# CC2340R5 register map
File version: 1.0
CPU: CM0P 1.0, other endian, MPU, FPU, 3 interrupt priority bits
Registers are 32-bit, read-write, reset 0x0 unless marked. A register's access mark holds for its fields unless they carry their own. Offsets are from the block's base; [hi:lo] are bit positions; 'fields as' and 'values as' point back to an identical list.

## CKMD — Clock Controller
Base 0x40001000
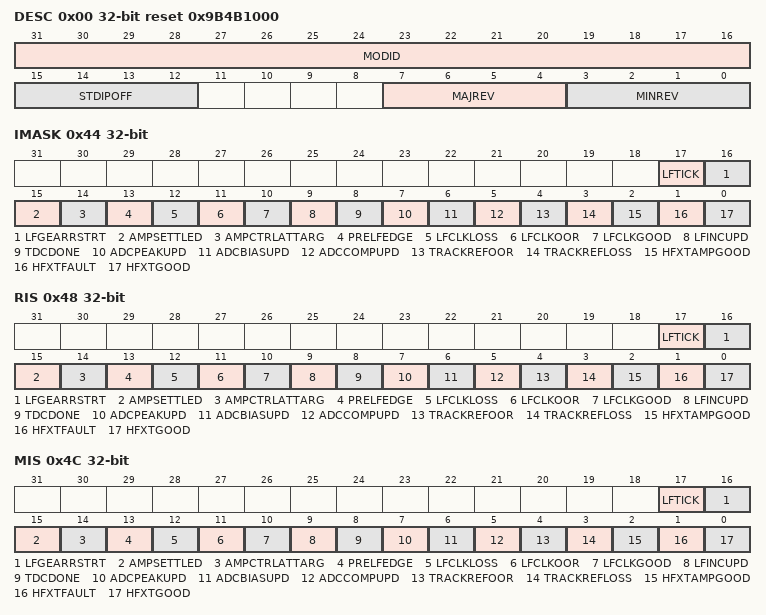
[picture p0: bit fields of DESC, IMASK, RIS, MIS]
0x00 DESC reset 0x9B4B1000 — Description Register. This register provides IP module ID, revision information, instance index and standard MMR registers offset.
  [31:16] MODID ro — [31:16] Module identifier used to uniquely identify this IP.
  [15:12] STDIPOFF ro — [15:12] Standard IP MMR block offset. Standard IP MMRs are the set of from aggregated IRQ registers till DTB. 0: Standard IP MMRs do not exist 0x1-0xF: Standard IP MMRs begin at offset of (64*STDIPOFF from the base IP address) NOTE: This IP does not have DTB as part of the Standard IP MMRs. It uses DTBCTL instead.
  [7:4] MAJREV ro — [7:4] Major revision of IP (0-15).
  [3:0] MINREV ro — [3:0] Minor revision of IP (0-15).
0x44 IMASK — Interrupt mask. This register selects interrupt sources which are allowed to pass from RIS to MIS when the corresponding bit-fields are set to 1.
  [17] LFTICK — [17:17] 32kHz TICK to RTC and WDT. Either derived from selected LFCLK or generated from CLKULL in absence of LFCLK.
  [16] LFGEARRSTRT — [16:16] LFINC filter gearing restart. Indicates that the LFINC filter restarted gearing. Subsequent LFINC estimates may have higher variation.
  [15] AMPSETTLED — [15:15] HFXT Amplitude compensation - settled Indicates that the amplitude compensation FSM has reached the SETTLED or TCXOMODE state, and the controls configured in HFXTTARG or HFXTDYN are reached.
  [14] AMPCTRLATTARG — [14:14] HFXT Amplitude compensation - controls at target Indicates that the control values configured in HFXTTARG or HFXTDYN are reached. Applies to Q1CAP, Q2CAP and IREF.
  [13] PRELFEDGE — [13:13] Pre-LF clock edge detect. Indicates that a positive edge occured on the selected pre-LF clock LFCLKSEL.PRE. Can be used by software to confirm that a LF clock source is running and within the expected frequency, before selecting it as the main LF clock source.
  [12] LFCLKLOSS — [12:12] LF clock is lost. Indicates that no LF clock edge occured for ~49us (~1.6 times nominal period). The system will automatically fall-back to generating LFTICK based on CLKULL, to avoid timing corruption. Note that this signal is NOT related to the analog LF clock-loss detector which can reset the device during STANDBY.
  [11] LFCLKOOR — [11:11] LF clock period out-of-range. Indicates that a LF clock period was measured to be out-of-range, according to LFQUALCTL.MAXERR.
  [10] LFCLKGOOD — [10:10] LF clock good. Indicates that the LF clock is good, according to the configuration in LFQUALCTL.
  [9] LFINCUPD — [9:9] LFINC updated. Indicates that a new LFINC measurement value is available in LFCLKSTAT.LFINC.
  [8] TDCDONE — [8:8] TDC done event. Indicates that the TDC measurement is done.
  [7] ADCPEAKUPD — [7:7] HFXT-ADC PEAK measurement update event. Indicates that the HFXT-ADC PEAK measurement is done.
  [6] ADCBIASUPD — [6:6] HFXT-ADC BIAS measurement update event. Indicates that the HFXT-ADC BIAS measurement is done.
  [5] ADCCOMPUPD — [5:5] HFXT-ADC comparison update event. Indicates that the HFXT-ADC comparison is done.
  [4] TRACKREFOOR — [4:4] Out-of-range indication from the tracking loop. Indicates that the selected reference clock frequency of the tracking loop is out-of-range.
  [3] TRACKREFLOSS — [3:3] Clock loss indication from the tracking loop. Indicates that the selected reference clock of the tracking loop is lost.
  [2] HFXTAMPGOOD — [2:2] HFXT amplitude good indication.
  [1] HFXTFAULT — [1:1] HFXT fault indication. Indicates that HFXT did not start correctly, or its frequency is too low. HFXT will not recover from this fault and has to be restarted. This is only a one-time check at HFXT startup.
  [0] HFXTGOOD — [0:0] HFXT good indication. Indicates that HFXT started correctly. The frequency is not necessarily good enough for radio operation. This is only a one-time check at HFXT startup.
0x48 RIS — Raw interrupt status. This register reflects the state of all pending interrupts, regardless of masking. This register allows the user to implement a poll scheme. A flag set in this register can be cleared by writing 1 to the corresponding ICLR register bit.
  [17] LFTICK ro — [17:17] 32kHz TICK to RTC and WDT. Either derived from selected LFCLK or generated from CLKULL in absence of LFCLK.
  [16] LFGEARRSTRT ro — [16:16] LFINC filter gearing restart. Indicates that the LFINC filter restarted gearing. Subsequent LFINC estimates may have higher variation.
  [15] AMPSETTLED ro — [15:15] HFXT Amplitude compensation - settled Indicates that the amplitude compensation FSM has reached the SETTLED or TCXOMODE state, and the controls configured in HFXTTARG or HFXTDYN are reached.
  [14] AMPCTRLATTARG ro — [14:14] HFXT Amplitude compensation - controls at target Indicates that the control values configured in HFXTTARG or HFXTDYN are reached. Applies to Q1CAP, Q2CAP and IREF.
  [13] PRELFEDGE ro — [13:13] Pre-LF clock edge detect. Indicates that a positive edge occured on the selected pre-LF clock LFCLKSEL.PRE. Can be used by software to confirm that a LF clock source is running and within the expected frequency, before selecting it as the main LF clock source.
  [12] LFCLKLOSS ro — [12:12] LF clock is lost. Indicates that no LF clock edge occured for ~49us (~1.6 times nominal period). The system will automatically fall-back to generating LFTICK based on CLKULL, to avoid timing corruption. Note that this signal is NOT related to the analog LF clock-loss detector which can reset the device during STANDBY.
  [11] LFCLKOOR ro — [11:11] LF clock period out-of-range. Indicates that a LF clock period was measured to be out-of-range, according to LFQUALCTL.MAXERR.
  [10] LFCLKGOOD ro — [10:10] LF clock good. Indicates that the LF clock is good, according to the configuration in LFQUALCTL.
  [9] LFINCUPD ro — [9:9] LFINC updated. Indicates that a new LFINC measurement value is available in LFCLKSTAT.LFINC.
  [8] TDCDONE ro — [8:8] TDC done event. Indicates that the TDC measurement is done.
  [7] ADCPEAKUPD ro — [7:7] HFXT-ADC PEAK measurement update event. Indicates that the HFXT-ADC PEAK measurement is done.
  [6] ADCBIASUPD ro — [6:6] HFXT-ADC BIAS measurement update event. Indicates that the HFXT-ADC BIAS measurement is done.
  [5] ADCCOMPUPD ro — [5:5] HFXT-ADC comparison update event. Indicates that the HFXT-ADC comparison is done.
  [4] TRACKREFOOR ro — [4:4] Out-of-range indication from the tracking loop. Indicates that the selected reference clock frequency of the tracking loop is out-of-range.
  [3] TRACKREFLOSS ro — [3:3] Clock loss indication from the tracking loop. Indicates that the selected reference clock of the tracking loop is lost.
  [2] HFXTAMPGOOD ro — [2:2] HFXT amplitude good indication.
  [1] HFXTFAULT ro — [1:1] HFXT fault indication. Indicates that HFXT did not start correctly, or its frequency is too low. HFXT will not recover from this fault and has to be restarted. This is only a one-time check at HFXT startup.
  [0] HFXTGOOD ro — [0:0] HFXT good indication. Indicates that HFXT started correctly. The frequency is not necessarily good enough for radio operation. This is only a one-time check at HFXT startup.
0x4C MIS — Masked interrupt status. This register is simply a bitwise AND of the contents of IMASK and RIS.*] registers. A flag set in this register can be cleared by writing 1 to the corresponding ICLR register bit.
  fields as RIS
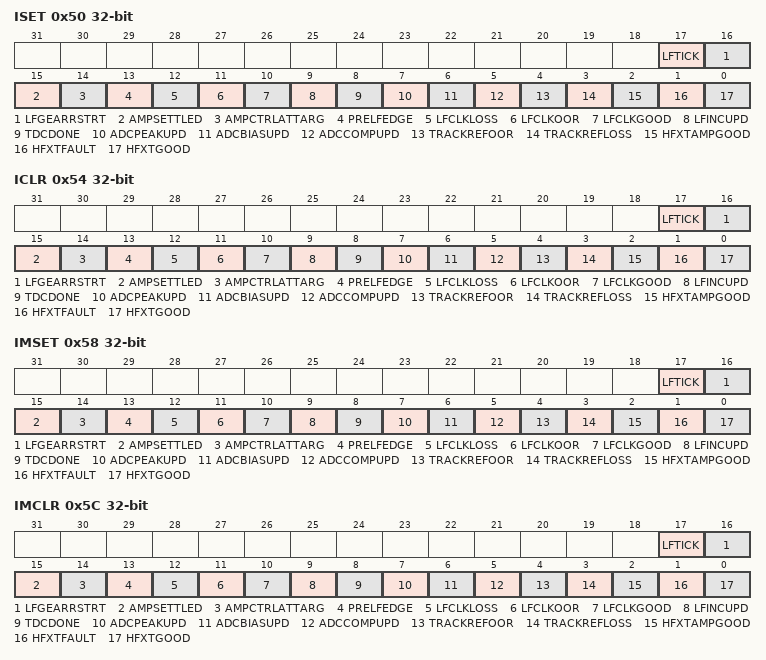
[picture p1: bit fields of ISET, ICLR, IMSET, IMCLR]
0x50 ISET — Interrupt set register. This register can used by software for diagnostics and safety checking purposes. Writing a 1 to a bit in this register will set the event and the corresponding RIS bit also gets set. If the corresponding IMASK bit is set, then the corresponding MIS register bit also gets set.
  [17] LFTICK wo — [17:17] 32kHz TICK to RTC and WDT. Either derived from selected LFCLK or generated from CLKULL in absence of LFCLK.
  [16] LFGEARRSTRT wo — [16:16] LFINC filter gearing restart. Indicates that the LFINC filter restarted gearing. Subsequent LFINC estimates may have higher variation.
  [15] AMPSETTLED wo — [15:15] HFXT Amplitude compensation - settled Indicates that the amplitude compensation FSM has reached the SETTLED or TCXOMODE state, and the controls configured in HFXTTARG or HFXTDYN are reached.
  [14] AMPCTRLATTARG wo — [14:14] HFXT Amplitude compensation - controls at target Indicates that the control values configured in HFXTTARG.Q1CAP, HFXTTARG.Q2CAP and HFXTTARG.IREF or HFXTDYN.Q1CAP, HFXTDYN.Q2CAP and HFXTDYN.IREF are reached.
  [13] PRELFEDGE wo — [13:13] Pre-LF clock edge detect. Indicates that a positive edge occured on the selected pre-LF clock LFCLKSEL.PRE. Can be used by software to confirm that a LF clock source is running and within the expected frequency, before selecting it as the main LF clock source.
  [12] LFCLKLOSS wo — [12:12] LF clock is lost. Indicates that no LF clock edge occured for ~49us (~1.6 times nominal period). The system will automatically fall-back to generating LFTICK based on CLKULL, to avoid timing corruption. Note that this signal is NOT related to the analog LF clock-loss detector which can reset the device during STANDBY.
  [11] LFCLKOOR wo — [11:11] LF clock period out-of-range. Indicates that a LF clock period was measured to be out-of-range, according to LFQUALCTL.MAXERR.
  [10] LFCLKGOOD wo — [10:10] LF clock good. Indicates that the LF clock is good, according to the configuration in LFQUALCTL.
  [9] LFINCUPD wo — [9:9] LFINC updated. Indicates that a new LFINC measurement value is available in LFCLKSTAT.LFINC.
  [8] TDCDONE wo — [8:8] TDC done event. Indicates that the TDC measurement is done.
  [7] ADCPEAKUPD wo — [7:7] HFXT-ADC PEAK measurement update event. Indicates that the HFXT-ADC PEAK measurement is done.
  [6] ADCBIASUPD wo — [6:6] HFXT-ADC BIAS measurement update event. Indicates that the HFXT-ADC BIAS measurement is done.
  [5] ADCCOMPUPD wo — [5:5] HFXT-ADC comparison update event. Indicates that the HFXT-ADC comparison is done.
  [4] TRACKREFOOR wo — [4:4] Out-of-range indication from the tracking loop. Indicates that the selected reference clock frequency of the tracking loop is out-of-range.
  [3] TRACKREFLOSS wo — [3:3] Clock loss indication from the tracking loop. Indicates that the selected reference clock of the tracking loop is lost.
  [2] HFXTAMPGOOD wo — [2:2] HFXT amplitude good indication.
  [1] HFXTFAULT wo — [1:1] HFXT fault indication. Indicates that HFXT did not start correctly, or its frequency is too low. HFXT will not recover from this fault and has to be restarted. This is only a one-time check at HFXT startup.
  [0] HFXTGOOD wo — [0:0] HFXT good indication. Indicates that HFXT started correctly. The frequency is not necessarily good enough for radio operation. This is only a one-time check at HFXT startup.
0x54 ICLR — Interrupt clear register. This register allows software to clear interrupts. Writing a 1 to a bit in this register will clear the event and the corresponding RIS bit also gets cleared. If the corresponding IMASK bit is set, then the corresponding MIS register bit also gets cleared.
  [17] LFTICK wo — [17:17] 32kHz TICK to RTC and WDT. Either derived from selected LFCLK or generated from CLKULL in absence of LFCLK.
  [16] LFGEARRSTRT wo — [16:16] LFINC filter gearing restart. Indicates that the LFINC filter restarted gearing. Subsequent LFINC estimates may have higher variation.
  [15] AMPSETTLED wo — [15:15] HFXT Amplitude compensation - settled Indicates that the amplitude compensation FSM has reached the SETTLED or TCXOMODE state, and the controls configured in HFXTTARG or HFXTDYN are reached.
  [14] AMPCTRLATTARG wo — [14:14] HFXT Amplitude compensation - controls at target Indicates that the control values configured in HFXTTARG or HFXTDYN are reached. Applies to Q1CAP, Q2CAP and IREF.
  [13] PRELFEDGE wo — [13:13] Pre-LF clock edge detect. Indicates that a positive edge occured on the selected pre-LF clock LFCLKSEL.PRE. Can be used by software to confirm that a LF clock source is running and within the expected frequency, before selecting it as the main LF clock source.
  [12] LFCLKLOSS wo — [12:12] LF clock is lost. Indicates that no LF clock edge occured for ~49us (~1.6 times nominal period). The system will automatically fall-back to generating LFTICK based on CLKULL, to avoid timing corruption. Note that this signal is NOT related to the analog LF clock-loss detector which can reset the device during STANDBY.
  [11] LFCLKOOR wo — [11:11] LF clock period out-of-range. Indicates that a LF clock period was measured to be out-of-range, according to LFQUALCTL.MAXERR.
  [10] LFCLKGOOD wo — [10:10] LF clock good. Indicates that the LF clock is good, according to the configuration in LFQUALCTL.
  [9] LFINCUPD wo — [9:9] LFINC updated. Indicates that a new LFINC measurement value is available in LFCLKSTAT.LFINC.
  [8] TDCDONE wo — [8:8] TDC done event. Indicates that the TDC measurement is done.
  [7] ADCPEAKUPD wo — [7:7] HFXT-ADC PEAK measurement update event. Indicates that the HFXT-ADC PEAK measurement is done.
  [6] ADCBIASUPD wo — [6:6] HFXT-ADC BIAS measurement update event. Indicates that the HFXT-ADC BIAS measurement is done.
  [5] ADCCOMPUPD wo — [5:5] HFXT-ADC comparison update event. Indicates that the HFXT-ADC comparison is done.
  [4] TRACKREFOOR wo — [4:4] Out-of-range indication from the tracking loop. Indicates that the selected reference clock frequency of the tracking loop is out-of-range.
  [3] TRACKREFLOSS wo — [3:3] Clock loss indication from the tracking loop. Indicates that the selected reference clock of the tracking loop is lost.
  [2] HFXTAMPGOOD wo — [2:2] HFXT amplitude good indication.
  [1] HFXTFAULT wo — [1:1] HFXT fault indication. Indicates that HFXT did not start correctly, or its frequency is too low. HFXT will not recover from this fault and has to be restarted. This is only a one-time check at HFXT startup.
  [0] HFXTGOOD wo — [0:0] HFXT good indication. Indicates that HFXT started correctly. The frequency is not necessarily good enough for radio operation. This is only a one-time check at HFXT startup.
0x58 IMSET — Interrupt mask set register. Writing a 1 to a bit in this register will set the corresponding IMASK bit.
  fields as ICLR
0x5C IMCLR — Interrupt mask clear register. Writing a 1 to a bit in this register will clear the corresponding IMASK bit.
  fields as ICLR
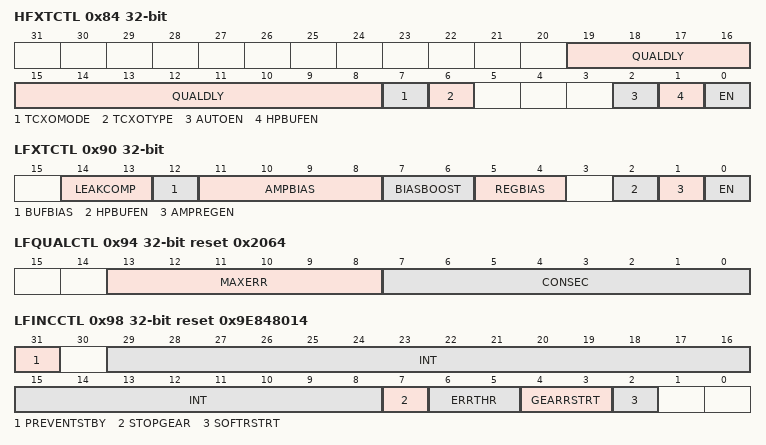
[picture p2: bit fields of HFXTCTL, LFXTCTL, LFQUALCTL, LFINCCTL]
0x84 HFXTCTL — High frequency crystal control
  [19:8] QUALDLY — [19:8] Skip potentially unstable clock cycles after enabling HFXT. Number of cycles skipped is 8*QUALDLY.
  [7] TCXOMODE — [7:7] Temperature compensated crystal oscillator mode. Set this bit if a TXCO is connected.
  [6] TCXOTYPE — [6:6] Type of temperature compensated crystal used. Only has effect if TCXOMODE is set.
    1=CMOS (Use with CMOS TCXO); 0=CLIPPEDSINE (Use with clipped-sine TCXO)
  [2] AUTOEN — [2:2] Automatic HFXT enable. If this bit is set, EN will automatically be set at wakeup or before (using pre-wake mechanism in PMCTL).
  [1] HPBUFEN — [1:1] High performance clock buffer enable. This bit controls the clock output for the RF PLL. It is required for radio operation.
  [0] EN — [0:0] HFXT enable. Setting this bit will enable HFXT. It will automatically be cleared upon STANDBY entry. If AUTOEN is set, this bit will be set automatically on wakeup or before (pre-wake mechanism in PMCTL).
0x8C LFOSCCTL — Low frequency oscillator control
  [0] EN — [0:0] LFOSC enable
0x90 LFXTCTL — Low frequency crystal control
  [14:13] LEAKCOMP — [14:13] Leakage compensation control
    3=OFF (No leakage compensation); 1=HALF (Half leakage compensation); 0=FULL (Full leakage compensation)
  [12] BUFBIAS — [12:12] Control the BIAS current of the input amp in LP buffer
    1=MAX (Maximum bias current: 50nA); 0=MIN (Minimum bias current: 25nA)
  [11:8] AMPBIAS — [11:8] Adjust current mirror ratio into oscillator core. This value is depending on crystal and is set by FW. This field uses a 2's complement encoding.
  [7:6] BIASBOOST — [7:6] Boost oscillator amplitude This value depends on the crystal and needs to be configured by Firmware.
  [5:4] REGBIAS — [5:4] Regulation loop bias resistor value This value depends on the crystal and needs to be configured by Firmware.
  [2] HPBUFEN — [2:2] Control the buffer used. In normal operation, low-power buffer is used in all device modes. The high-performance buffer is only used for test purposes.
  [1] AMPREGEN — [1:1] Amplitude regulation loop enable
  [0] EN — [0:0] LFXT enable
0x94 LFQUALCTL reset 0x2064 — Low frequency clock qualification control
  [13:8] MAXERR — [13:8] Maximum LFCLK period error. Value given in microseconds, 3 integer bits + 3 fractional bits.
  [7:0] CONSEC — [7:0] Number of consecutive times the LFCLK period error has to be smaller than MAXERR to be considered "good". Setting this value to 0 will bypass clock qualification, and the "good" indicator will always be 1.
0x98 LFINCCTL reset 0x9E848014 — Low frequency time increment control
  [31] PREVENTSTBY — [31:31] Controls if the LFINC filter prevents STANBY entry until settled.
    1=ON (Enable. Prevent STANDBY entry.); 0=OFF (Disable. Do not prevent STANDBY entry.)
  [29:8] INT — [29:8] Integral part of the LFINC filter. This value is updated by Hardware to reflect the current state of the filter. It can also be written to change the current state.
  [7] STOPGEAR — [7:7] Controls the final gear of the LFINC filter.
    1=HIGH (Highest final gear. Best dynamic frequency tracking, but higher variation in filter value.); 0=LOW (Lowest final gear. Best settling, but less dynamic frequency tracking.)
  [6:5] ERRTHR — [6:5] Controls the threshold for gearing restart of the LFINC filter. Only effective if GEARRSTRT is not ONETHR or TWOTHR.
    3=SMALL (Restart gearing on small error. Potentially more false restarts, faster response on small frequency shifts.); 2=MIDSMALL (Middle value towards SMALL.); 1=MIDLARGE (Middle value towards LARGE.); 0=LARGE (Restart gearing on large error. Fewer false restarts, slower response on small frequency shifts.)
  [4:3] GEARRSTRT — [4:3] Controls gearing restart of the LFINC filter.
    2=TWOTHR (Restart gearing when the error accumulator crosses the threshold twice in a row.); 1=ONETHR (Restart gearing when the error accumulator crosses the threshold once.); 0=NEVER (Never restart gearing. Very stable filter value, but very slow response on frequency changes.)
  [2] SOFTRSTRT — [2:2] Use a higher gear after re-enabling / wakeup. The filter will require 16-24 LFCLK periods to settle (depending on STOPGEAR), but may respond faster to frequency changes during STANDBY.
    1=ON (Use soft gearing restarts); 0=OFF (Don't use soft gearing restarts)
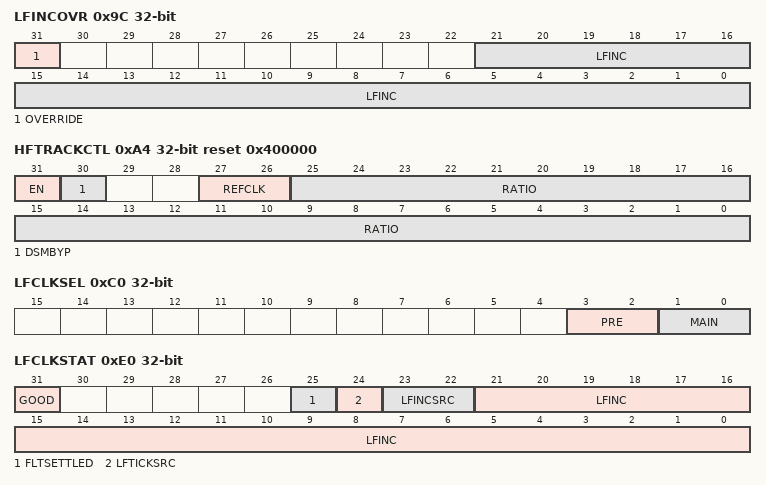
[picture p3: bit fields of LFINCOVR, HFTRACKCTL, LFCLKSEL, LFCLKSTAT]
0x9C LFINCOVR — Low frequency time increment override control
  [31] OVERRIDE — [31:31] Override LF increment Use the value provided in LFINC instead of the value calculated by Hardware.
  [21:0] LFINC — [21:0] LF increment value This value is used when OVERRIDE is set to 1. Otherwise the value is calculated automatically.
0xA4 HFTRACKCTL reset 0x400000 — High frequency tracking loop control
  [31] EN — [31:31] Enable tracking loop.
  [30] DSMBYP — [30:30] Bypass Delta-Sigma-Modulation of fine trim.
  [27:26] REFCLK — [27:26] Select the reference clock for the tracking loop. Change only while the tracking loop is disabled.
    2=GPI (Select GPI as reference clock.); 1=LRF (Select LRF reference clock.); 0=HFXT (Select HFXT as reference clock.)
  [25:0] RATIO — [25:0] Reference clock ratio. RATIO = 24MHz / (2*reference-frequency) * 2^24 Commonly used reference clock frequencies are provided as enumerations.
    0x3000000=REF4M (Use for 4MHz reference clock); 0x1800000=REF8M (Use for 8MHz reference clock); 0x400000=REF48M (Use for 48MHz reference clock)
0xAC NABIASCTL — Nanoamp-bias control
  [0] EN — [0:0] Enable nanoamp-bias
0xB0 LFMONCTL — Low-frequency clock-monitor control
  [0] EN — [0:0] Enable LFMONITOR. Enable only after a LF clock source has been selected, enabled and is stable. If LFMONITOR detects a clock loss, the system will be reset.
0xC0 LFCLKSEL — Low frequency clock selection
  [3:2] PRE — [3:2] Select low frequency clock source for the PRELFCLK interrupt. Can be used by Software to confirm that the clock is running and it's frequency is good, before selecting it in MAIN.
    3=EXTLF (External LF clock through GPI.); 2=LFXT (Low frequency crystal oscillator); 1=LFOSC (Low frequency on-chip oscillator); 0=NONE (No clock. Output will be tied low.)
  [1:0] MAIN — [1:0] Select the main low frequency clock source. If running, this clock will be used to generate LFTICK and as CLKULL during STANDBY. If not running, LFTICK will be generated from HFOSC and STANDBY entry will be prevented.
    3=EXTLF (External LF clock through GPI.); 2=LFXT (Low frequency crystal oscillator); 1=LFOSC (Low frequency on-chip oscillator); 0=FAKE (No LF clock selected. LFTICK will be generated from HFOSC, STANDBY entry will be prevented.)
0xC8 ADCCLKSEL — ADC clock selection
  [1:0] SRC — [1:0] Select ADC clock source Change only while ADC is disabled.
    1=HFXT (48MHz HFXT); 0=CLKSVT (48MHz CLKSVT)
0xE0 LFCLKSTAT — Low-frequency clock status
  [31] GOOD ro — [31:31] Low frequency clock good Note: This is only a coarse frequency check based on LFQUALCTL. The clock may not be accurate enough for timing purposes.
  [25] FLTSETTLED ro — [25:25] LFINC filter is running and settled.
  [24] LFTICKSRC ro — [24:24] Source of LFTICK.
    1=FAKE (LFTICK generated from CLKULL (LFCLK not available)); 0=LFCLK (LFTICK generated from the selected LFCLK)
  [23:22] LFINCSRC ro — [23:22] Source of LFINC used by the RTC. This value depends on LFINCOVR.OVERRIDE, LF clock availability, HF tracking loop status and the device state (ACTIVE/STANDBY).
    3=FAKE (Using FAKE LFTICKs with corresponding LFINC value.); 2=OVERRIDE (Using override value from LFINCOVR.LFINC); 1=AVG (Using filtered / average value. This value is updated by hardware and can be read and updated in LFINCCTL.INT.); 0=MEAS (Using measured value. This value is updated by hardware and can be read from LFINC.)
  [21:0] LFINC ro — [21:0] Measured value of LFINC. Given in microseconds with 16 fractional bits. This value is calculated by Hardware. It is the LFCLK period according to CLKULL cycles.
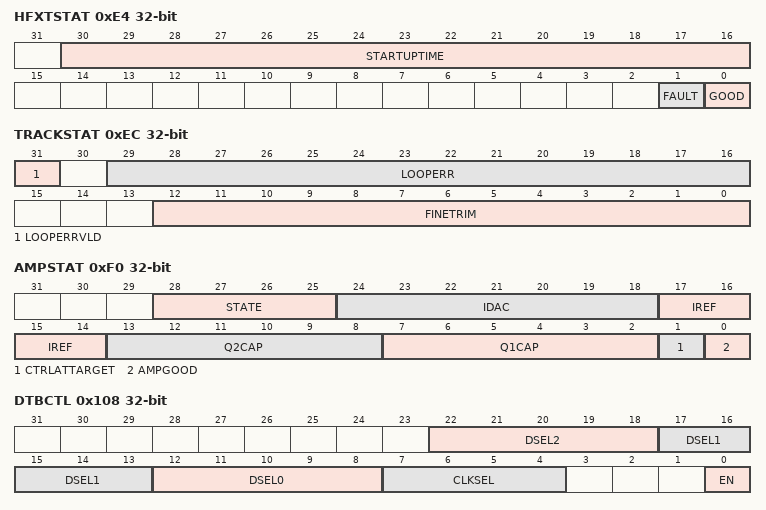
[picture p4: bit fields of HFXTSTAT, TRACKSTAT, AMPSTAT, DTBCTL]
0xE4 HFXTSTAT — HFXT status information
  [30:16] STARTUPTIME ro — [30:16] HFXT startup time Can be used by software to plan starting HFXT ahead in time. Measured whenever HFXT is enabled in CLKULL periods (24MHz), from HFXTCTL.EN until the clock is good for radio operation (amplitude compensation is settled).
  [1] FAULT ro — [1:1] HFXT clock fault Indicates a lower than expected HFXT frequency. HFXT will not recover from this fault, disabling and re-enabling HFXT is required.
  [0] GOOD ro — [0:0] HFXT clock available. The frequency is not necessarily good enough for radio operation.
0xEC TRACKSTAT — HFOSC tracking loop status information
  [31] LOOPERRVLD ro — [31:31] Current HFOSC tracking error valid This bit is one if the tracking loop is running and the error value is valid.
  [29:16] LOOPERR ro — [29:16] Current HFOSC tracking error
  [12:0] FINETRIM ro — [12:0] Current HFOSC Fine-trim value This field uses the internal fractional representation (sign, 4 integer bits, 8 fractional bits). The actual trim value applied to the oscillator is delta-sigma modulated 5 bits non-signed (inverted sign bit + integer bits).
0xF0 AMPSTAT — HFXT Amplitude Compensation Status
  [28:25] STATE ro — [28:25] Current AMPCOMP FSM state.
    15=SETTLED (Settled state); 14=UPDATEUP (Amplitude up correction); 12=TXCOMODE (TCXO settled state); 10=SHUTDN0 (First shutdown state); 7=INJWAIT (Post injection settle wait); 6=UPDATEDN (Amplitude down correction); 5=RAMP0 (Initial amplitude ramping with HFXTINIT values); 4=RAMP1 (Transition to HFXTTARG values); 3=INJECT (Injecting HFOSC for fast startup); 2=SHUTDN1 (Second shutdown state); 1=LDOSTART (Starting LDO); 0=IDLE (FSM in idle state)
  [24:18] IDAC ro — [24:18] Current IDAC control value.
  [17:14] IREF ro — [17:14] Current IREF control value.
  [13:8] Q2CAP ro — [13:8] Current Q2CAP control value.
  [7:2] Q1CAP ro — [7:2] Current Q1CAP control value.
  [1] CTRLATTARGET ro — [1:1] HFXT control values match target values. This applies to IREF, Q1CAP, Q2CAP values.
  [0] AMPGOOD ro — [0:0] HFXT amplitude good
0x108 DTBCTL — Digital test bus mux control
  [22:18] DSEL2 — [22:18] Select data to output on DTB[15:11]
  [17:13] DSEL1 — [17:13] Select data to output on DTB[10:6]
  [12:8] DSEL0 — [12:8] Select data to output on DTB[5:1]
  [7:4] CLKSEL — [7:4] Select clock to output on DTB[0]
  [0] EN — [0:0] Enable DTB output
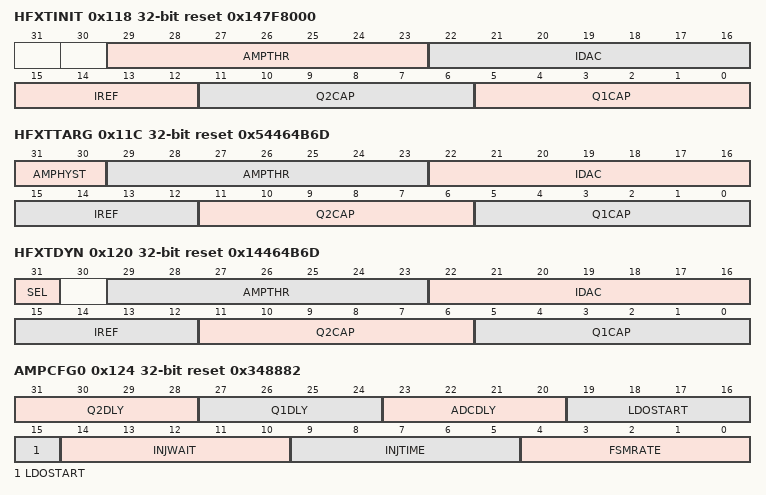
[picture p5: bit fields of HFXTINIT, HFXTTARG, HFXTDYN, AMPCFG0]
0x118 HFXTINIT reset 0x147F8000 — Initial values for HFXT ramping
  [29:23] AMPTHR — [29:23] Amplitude threshold during HFXT ramping
  [22:16] IDAC — [22:16] Initial HFXT IDAC current
  [15:12] IREF — [15:12] Initial HFXT IREF current
  [11:6] Q2CAP — [11:6] Initial HFXT Q2 cap trim
  [5:0] Q1CAP — [5:0] Initial HFXT Q1 cap trim
0x11C HFXTTARG reset 0x54464B6D — Target values for HFXT ramping
  [31:30] AMPHYST — [31:30] ADC hysteresis used during IDAC updates. Every AMPCFG1.INTERVAL, IDAC will be regulated - up as long as ADC $lt; AMPTHR - down as long as ADC $gt; AMPTHR+AMPHYST
  [29:23] AMPTHR — [29:23] Minimum HFXT amplitude
  [22:16] IDAC — [22:16] Minimum IDAC current
  [15:12] IREF — [15:12] Target HFXT IREF current
  [11:6] Q2CAP — [11:6] Target HFXT Q2 cap trim
  [5:0] Q1CAP — [5:0] Target HFXT Q1 cap trim
0x120 HFXTDYN reset 0x14464B6D — Alternative target values for HFXT configuration Software can change these values to dynamically transition the HFXT configuration while HFXT is running. Set SEL to select the alternative set of target values.
  [31] SEL — [31:31] Select the dynamic configuration. Amplitude ramping will always happen using the values in HFXTINIT, and HFXTTARG. Afterwards, this bit can be used to select between HFXTTARG and HFXTDYN. Hardware will ensure a smooth transition of analog control signals.
    1=DYNAMIC (Select configuration in HFXTDYN.); 0=TARGET (Select configuration in HFXTTARG.)
  [29:23] AMPTHR — [29:23] Minimum HFXT amplitude
  [22:16] IDAC — [22:16] Minimum IDAC current
  [15:12] IREF — [15:12] Target HFXT IREF current
  [11:6] Q2CAP — [11:6] Target HFXT Q2 cap trim
  [5:0] Q1CAP — [5:0] Target HFXT Q1 cap trim
0x124 AMPCFG0 reset 0x348882 — Amplitude Compensation Configuration 0
  [31:28] Q2DLY — [31:28] Q2CAP change delay. Number of clock cycles to wait before changing Q2CAP by one step. Clock frequency defined in FSMRATE.
  [27:24] Q1DLY — [27:24] Q1CAP change delay. Number of clock cycles to wait before changing Q1CAP by one step. Clock frequency defined in FSMRATE.
  [23:20] ADCDLY — [23:20] ADC and PEAKDET startup time. Number of clock cycles to wait after enabling the PEAKDET and ADC before the first measurement. Clock frequency defined in FSMRATE.
  [19:15] LDOSTART — [19:15] LDO startup time. Number of clock cycles to bypass the LDO resistors for faster startup. Clock frequency defined in FSMRATE.
  [14:10] INJWAIT — [14:10] Inject HFOSC for faster HFXT startup. This value specifies the number of clock cycles to wait after injection is done. The clock speed is defined in FSMRATE.
  [9:5] INJTIME — [9:5] Inject HFOSC for faster HFXT startup. This value specifies the number of clock cycles the injection is enabled. The clock speed is defined in FSMRATE. Set to 0 to disable injection.
  [4:0] FSMRATE — [4:0] Update rate for the AMPCOMP update rate. Also affects the clock rate for the Amplitude ADC. The update rate is 6MHz / (FSMRATE+1).
    23=_250K (250 kHz); 11=_500K (500 kHz); 5=_1M (1 MHz); 2=_2M (2 MHz); 1=_3M (3 MHz); 0=_6M (6 MHz)
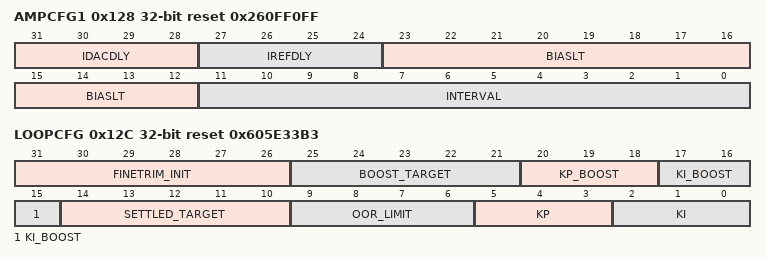
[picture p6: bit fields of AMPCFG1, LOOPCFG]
0x128 AMPCFG1 reset 0x260FF0FF — Amplitude Compensation Configuration 1
  [31:28] IDACDLY — [31:28] IDAC change delay. Time to wait before changing IDAC by one step. This time needs to be long enough for the crystal to settle. The number of clock cycles to wait is IDACDLY$lt;$lt;4 + 15. Clock frequency defined in AMPCFG0.FSMRATE.
  [27:24] IREFDLY — [27:24] IREF change delay. Number of clock cycles to wait before changing IREF by one step. Clock frequency defined in AMPCFG0.FSMRATE.
  [23:12] BIASLT — [23:12] Lifetime of the amplitude ADC bias value. This value specifies the number of adjustment intervals, until the ADC bias value has to be measured again. Set to 0 to disable automatic bias measurements.
  [11:0] INTERVAL — [11:0] Interval for amplitude adjustments. Set to 0 to disable periodic adjustments. This value specifies the number of clock cycles between adjustments. The clock speed is defined in AMPCFG0.FSMRATE.
0x12C LOOPCFG reset 0x605E33B3 — Configuration Register for the Tracking Loop
  [31:26] FINETRIM_INIT — [31:26] Initial value for the resistor fine trim
  [25:21] BOOST_TARGET — [25:21] Number of error-updates using BOOST values, before using KI/KP
  [20:18] KP_BOOST — [20:18] Proportional loop coefficient during BOOST
  [17:15] KI_BOOST — [17:15] Integral loop coefficient during BOOST
  [14:10] SETTLED_TARGET — [14:10] Number of updates before HFOSC is considered "settled"
  [9:6] OOR_LIMIT — [9:6] Out-of-range threshold
  [5:3] KP — [5:3] Proportional loop coefficient
  [2:0] KI — [2:0] Integral loop coefficient
0x300 WDTCNT — WDT counter value register
  [31:0] VAL — [31:0] Counter value. A write to this field immediately starts (or restarts) the counter. It will count down from the written value. If the counter reaches 0, a reset will be generated. A write value of 0 immediately generates a reset. This field is only writable if not locked. See WDTLOCK register. Writing this field will automatically activate the lock. A read returns the current value of the counter.
0x304 WDTTEST — WDT test mode register
  [0] STALLEN — [0:0] WDT stall enable This field is only writable if not locked. See WDTLOCK register.
    1=EN (ENABLE WDT stops counting while the CPU is stopped by a debugger.); 0=DIS (DISABLE WDT continues counting while the CPU is stopped by a debugger.)
0x308 WDTLOCK reset 0x1
  [31:0] STAT — [31:0] A write with value 0x1ACCE551 unlocks the watchdog registers for write access. A write with any other value locks the watchdog registers for write access. Writing the WDTCNT register will also lock the watchdog registers. A read of this field returns the state of the lock (0=unlocked, 1=locked).
